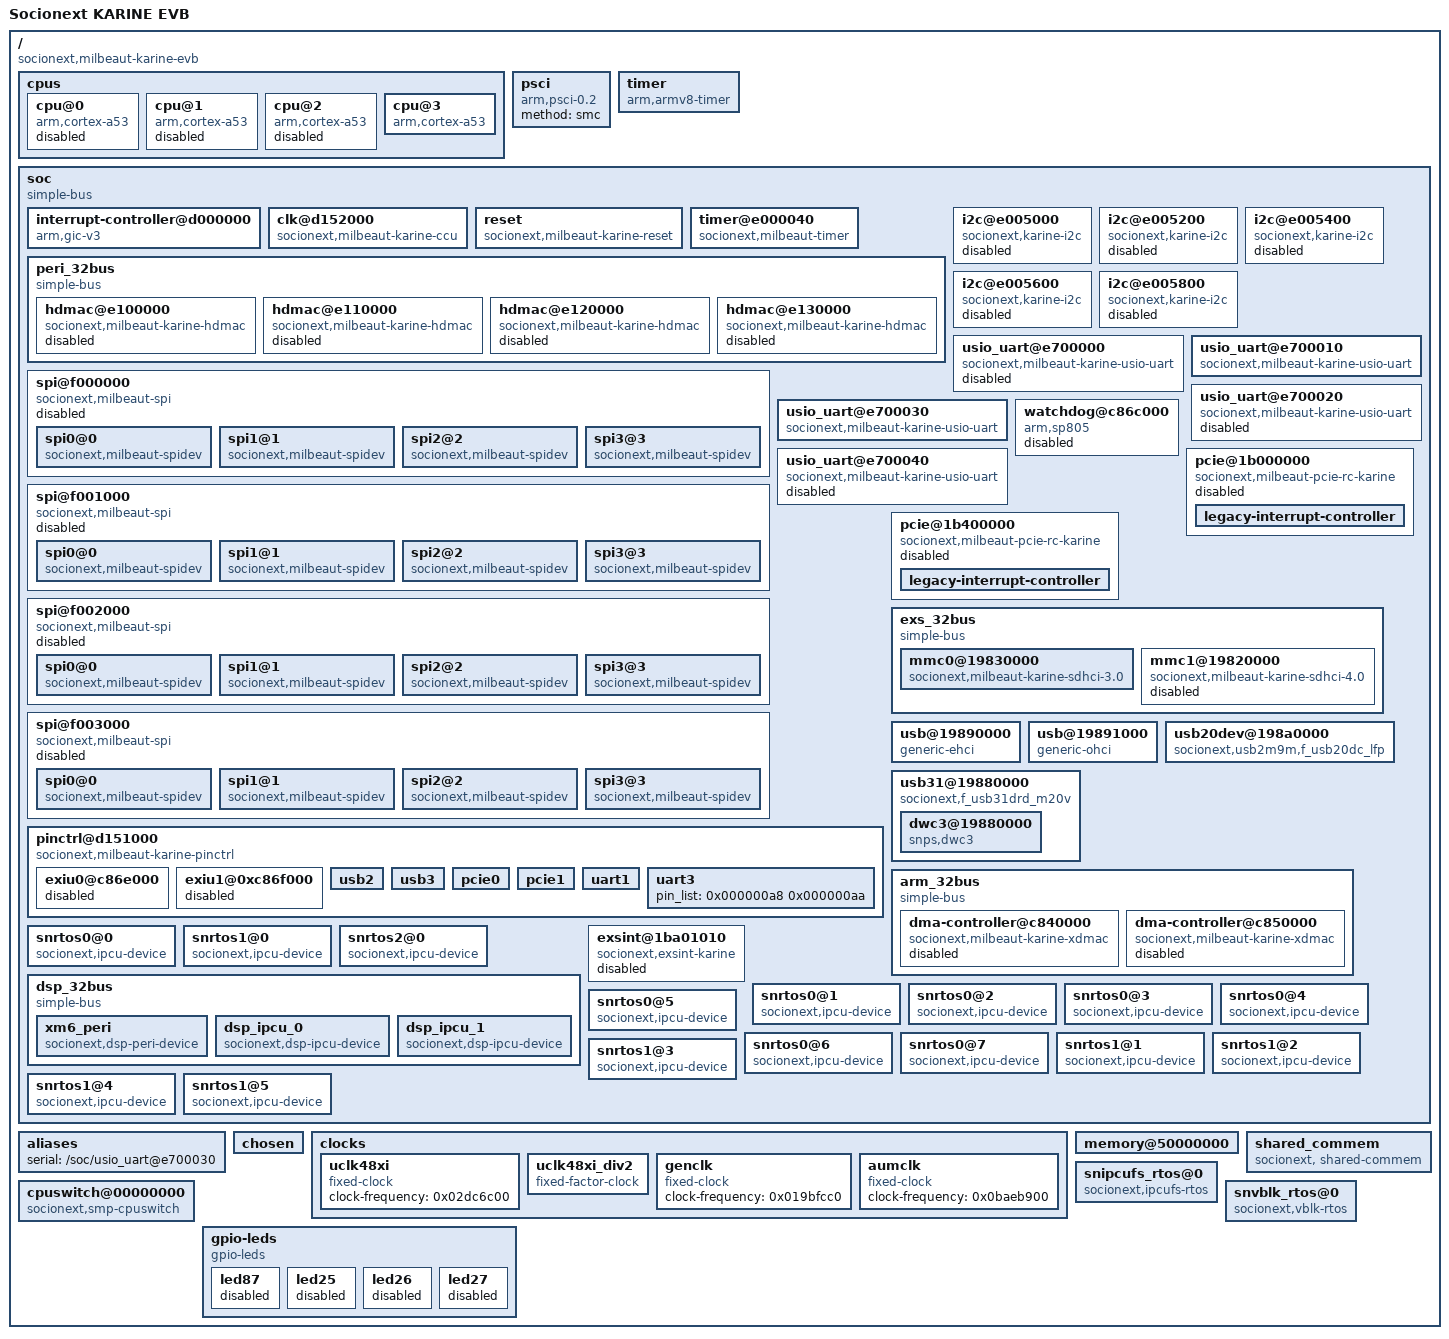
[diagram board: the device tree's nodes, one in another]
/dts-v1/;
// version:		17
// last_comp_version:	16
// boot_cpuid_phys:	0x0

/ {
    compatible = "socionext,milbeaut-karine-evb", "socionext,karine";
    #address-cells = <0x00000002>;
    #size-cells = <0x00000002>;
    interrupt-parent = <0x00000001>;
    model = "Socionext KARINE EVB";
    cpus {
        #address-cells = <0x00000001>;
        #size-cells = <0x00000000>;
        cpu@0 {
            device_type = "cpu";
            compatible = "arm,cortex-a53";
            reg = <0x00000000>;
            enable-method = "psci";
            status = "disabled";
        };
        cpu@1 {
            device_type = "cpu";
            compatible = "arm,cortex-a53";
            reg = <0x00000001>;
            enable-method = "psci";
            status = "disabled";
        };
        cpu@2 {
            device_type = "cpu";
            compatible = "arm,cortex-a53";
            reg = <0x00000002>;
            enable-method = "psci";
            status = "disabled";
        };
        cpu@3 {
            device_type = "cpu";
            compatible = "arm,cortex-a53";
            reg = <0x00000003>;
            enable-method = "psci";
            status = "okay";
        };
    };
    psci {
        compatible = "arm,psci-0.2";
        method = "smc";
    };
    timer {
        compatible = "arm,armv8-timer";
        interrupts = <0x00000001 0x0000000d 0x00000f04 0x00000001 0x0000000e 0x00000f04 0x00000001 0x0000000b 0x00000f04 0x00000001 0x0000000a 0x00000f04>;
    };
    soc {
        compatible = "simple-bus";
        #address-cells = <0x00000002>;
        #size-cells = <0x00000002>;
        ranges = <0x00000000 0x00000000 0x00000000 0x00000000 0x00000000 0xffffffff>;
        dma-ranges = <0x00000000 0x00000000 0x00000000 0x00000000 0x00000000 0xfffffffe>;
        interrupt-controller@d000000 {
            compatible = "arm,gic-v3";
            #interrupt-cells = <0x00000003>;
            interrupt-controller;
            #redistributor-regions = <0x00000001>;
            reg = <0x00000000 0x0d000000 0x00000000 0x00010000 0x00000000 0x0d080000 0x00000000 0x00080000>;
            black-list = <0x00000000 0x00000001 0x00000002 0x00000003 0x00000004 0x00000005 0x00000006 0x0000000a 0x0000000c 0x0000000d 0x00000010 0x00000012 0x00000013 0x00000016 0x00000017 0x00000019 0x0000001c 0x0000001e 0x00000020 0x00000021 0x00000023 0x00000025 0x00000027 0x00000028 0x00000029 0x0000002a 0x0000002c 0x0000002d 0x00000030 0x00000032 0x00000033 0x00000036 0x00000037 0x00000039 0x0000003c 0x0000003e 0x00000040 0x00000041 0x00000043 0x00000045 0x00000047 0x00000048 0x00000049 0x0000004a 0x0000004b 0x0000004c 0x0000004d 0x0000004e 0x0000004f 0x00000050 0x00000051 0x00000052 0x00000053 0x00000054 0x00000055 0x00000056 0x00000057 0x00000058 0x00000059 0x0000005a 0x0000005b 0x00000060 0x00000061 0x00000062 0x00000063 0x00000064 0x00000065 0x00000066 0x00000067 0x00000068 0x00000069 0x0000006a 0x0000006b 0x0000006c 0x0000006d 0x0000006e 0x0000006f 0x00000070 0x00000071 0x00000072 0x00000073 0x00000074 0x00000075 0x00000076 0x00000077 0x00000078 0x00000079 0x0000007a 0x0000007b 0x0000007c 0x0000007d 0x0000007e 0x0000007f 0x00000080 0x00000081 0x00000082 0x00000083 0x00000084 0x00000085 0x00000086 0x00000087 0x00000088 0x00000089 0x0000008a 0x0000008b 0x0000008c 0x0000008d 0x0000008e 0x0000008f 0x00000090 0x00000091 0x00000092 0x00000093 0x00000094 0x00000095 0x00000096 0x00000097 0x00000098 0x00000099 0x0000009a 0x0000009b 0x0000009c 0x0000009d 0x0000009e 0x0000009f 0x000000a0 0x000000a1 0x000000a2 0x000000a3 0x000000a4 0x000000a5 0x000000a6 0x000000a7 0x000000a8 0x000000a9 0x000000aa 0x000000ab 0x000000ac 0x000000ad 0x000000ae 0x000000af 0x000000b0 0x000000b1 0x000000b2 0x000000b3 0x000000b4 0x000000b5 0x000000b6 0x000000b7 0x000000b8 0x000000b9 0x000000ba 0x000000bb 0x000000bc 0x000000bd 0x000000be 0x000000bf 0x000000c0 0x000000c1 0x000000c2 0x000000c3 0x000000c4 0x000000c5 0x000000c6 0x000000c7 0x000000c8 0x000000c9 0x000000ca 0x000000cb 0x000000cc 0x000000cd 0x000000ce 0x000000cf 0x000000d0 0x000000d1 0x000000d2 0x000000d3 0x000000d4 0x000000d5 0x000000d6 0x000000d7 0x000000d8 0x000000d9 0x000000da 0x000000db 0x000000dc 0x000000dd 0x000000de 0x000000df 0x000000e0 0x000000e1 0x000000e2 0x000000e3 0x000000e4 0x000000e5 0x000000e6 0x000000e7 0x000000e8 0x000000e9 0x000000ea 0x000000eb 0x000000ec 0x000000ed 0x000000f2 0x000000f3 0x000000f4 0x000000f5 0x000000f6 0x000000f8 0x000000f9 0x00000102 0x00000103 0x00000108 0x00000109 0x0000010a 0x0000010b 0x0000010c 0x0000010f 0x00000110 0x00000111 0x00000112 0x00000113 0x00000114 0x00000115 0x00000116 0x00000117 0x00000118 0x00000119 0x0000011a 0x0000011b 0x0000011c 0x0000011d 0x0000011e 0x0000011f 0x00000120 0x00000121 0x00000122 0x00000123 0x00000124 0x00000125 0x00000126 0x00000127 0x00000128 0x00000129 0x0000012a 0x0000012b 0x0000012c 0x0000012d 0x0000012e 0x0000012f 0x00000130 0x00000131 0x00000132 0x00000133 0x00000134 0x00000135 0x00000136 0x00000137 0x00000138 0x00000139 0x0000013a 0x0000013b 0x0000013c 0x0000013d 0x0000013e 0x0000013f 0x00000140 0x00000141 0x00000142 0x00000143 0x00000144 0x00000145 0x00000146 0x00000147 0x00000148 0x00000149 0x0000014a 0x0000014b 0x0000014c 0x0000014e 0x00000150 0x00000151 0x00000152 0x00000153 0x00000155 0x00000157 0x00000158 0x00000159 0x0000015a 0x0000015b 0x0000015c 0x0000015d 0x0000015e 0x0000015f 0x00000160 0x00000161 0x00000162 0x00000163 0x00000164 0x00000165 0x00000166 0x00000167 0x00000168 0x00000169 0x0000016a 0x0000016b 0x0000016c 0x0000016d 0x0000016e 0x0000016f 0x00000170 0x00000171 0x00000172 0x00000173 0x00000174 0x00000175 0x00000176 0x00000177 0x00000178 0x00000179 0x0000017a 0x0000017b 0x0000017c 0x0000017d 0x0000017e 0x0000017f 0x00000180 0x00000181 0x00000182 0x00000183 0x00000184 0x00000185 0x00000186 0x00000187 0x00000188 0x00000189 0x0000018a 0x0000018b 0x0000018c 0x0000018d 0x0000018e 0x0000018f 0x00000190 0x00000191 0x00000192 0x00000193 0x00000194 0x00000195 0x00000196 0x00000197 0x00000198 0x00000199 0x0000019a 0x0000019b 0x0000019c 0x0000019d 0x0000019e 0x0000019f>;
            interrupts = <0x00000001 0x00000009 0x00000004>;
            phandle = <0x00000001>;
        };
        clk@d152000 {
            compatible = "socionext,milbeaut-karine-ccu";
            reg = <0x00000000 0x0d152000 0x00000000 0x00003000>;
            #clock-cells = <0x00000001>;
            clocks = <0x00000002 0x00000003 0x00000004>;
            clock-names = "UCLKXI", "AUMCLKI", "GENCLK";
            phandle = <0x00000005>;
        };
        reset {
            compatible = "socionext,milbeaut-karine-reset";
            #reset-cells = <0x00000001>;
            phandle = <0x00000007>;
        };
        timer@e000040 {
            compatible = "socionext,milbeaut-timer";
            reg = <0x00000000 0x0e000040 0x00000000 0x00000020>;
            interrupts = <0x00000000 0x0000010d 0x00000004>;
            clocks = <0x00000005 0x0000000a>;
            rating = <0x0000012c>;
        };
        peri_32bus {
            compatible = "simple-bus";
            #address-cells = <0x00000001>;
            #size-cells = <0x00000001>;
            ranges = <0x00000000 0x00000000 0x00000000 0xffffffff>;
            dma-ranges = <0x00000000 0x00000000 0x00000000 0xfffffffe>;
            hdmac@e100000 {
                compatible = "socionext,milbeaut-karine-hdmac";
                reg = <0x0e100000 0x00010000>;
                interrupts = <0x00000000 0x0000012c 0x00000004 0x00000000 0x0000012d 0x00000004 0x00000000 0x0000012e 0x00000004 0x00000000 0x0000012f 0x00000004 0x00000000 0x00000130 0x00000004 0x00000000 0x00000131 0x00000004 0x00000000 0x00000132 0x00000004 0x00000000 0x00000133 0x00000004>;
                #dma-cells = <0x00000001>;
                priority-rotate;
                clocks = <0x00000005 0x00000010>;
                status = "disabled";
                phandle = <0x00000006>;
            };
            hdmac@e110000 {
                compatible = "socionext,milbeaut-karine-hdmac";
                reg = <0x0e110000 0x00010000>;
                interrupts = <0x00000000 0x00000134 0x00000004 0x00000000 0x00000135 0x00000004 0x00000000 0x00000136 0x00000004 0x00000000 0x00000137 0x00000004 0x00000000 0x00000138 0x00000004 0x00000000 0x00000139 0x00000004 0x00000000 0x0000013a 0x00000004 0x00000000 0x0000013b 0x00000004>;
                #dma-cells = <0x00000001>;
                priority-rotate;
                clocks = <0x00000005 0x00000010>;
                status = "disabled";
            };
            hdmac@e120000 {
                compatible = "socionext,milbeaut-karine-hdmac";
                reg = <0x0e120000 0x00010000>;
                interrupts = <0x00000000 0x0000013c 0x00000004 0x00000000 0x0000013d 0x00000004 0x00000000 0x0000013e 0x00000004 0x00000000 0x0000013f 0x00000004 0x00000000 0x00000140 0x00000004 0x00000000 0x00000141 0x00000004 0x00000000 0x00000142 0x00000004 0x00000000 0x00000143 0x00000004>;
                #dma-cells = <0x00000001>;
                priority-rotate;
                clocks = <0x00000005 0x00000010>;
                status = "disabled";
            };
            hdmac@e130000 {
                compatible = "socionext,milbeaut-karine-hdmac";
                reg = <0x0e130000 0x00010000>;
                interrupts = <0x00000000 0x00000144 0x00000004 0x00000000 0x00000145 0x00000004 0x00000000 0x00000146 0x00000004 0x00000000 0x00000147 0x00000004 0x00000000 0x00000148 0x00000004 0x00000000 0x00000149 0x00000004 0x00000000 0x0000014a 0x00000004 0x00000000 0x0000014b 0x00000004>;
                #dma-cells = <0x00000001>;
                priority-rotate;
                clocks = <0x00000005 0x00000010>;
                status = "disabled";
            };
        };
        spi@f000000 {
            compatible = "socionext,milbeaut-spi";
            clocks = <0x00000005 0x0000001c 0x00000005 0x0000001b>;
            interrupts = <0x00000000 0x0000015a 0x00000004>;
            reg = <0x00000000 0x0f000000 0x00000000 0x00001000>;
            #address-cells = <0x00000001>;
            #size-cells = <0x00000000>;
            dmas = <0x00000006 0x0000001c 0x00000006 0x0000001b>;
            dma-names = "tx", "rx";
            fifo-size = <0x00000080>;
            num-cs = <0x00000004>;
            dma-mode = <0x00000001>;
            status = "disabled";
            spi0@0 {
                compatible = "socionext,milbeaut-spidev";
                reg = <0x00000000>;
                spi-max-frequency = <0x00989680>;
                ssout-cont = <0x00000002>;
            };
            spi1@1 {
                compatible = "socionext,milbeaut-spidev";
                reg = <0x00000001>;
                spi-max-frequency = <0x00989680>;
                ssout-cont = <0x00000002>;
            };
            spi2@2 {
                compatible = "socionext,milbeaut-spidev";
                reg = <0x00000002>;
                spi-max-frequency = <0x00989680>;
                ssout-cont = <0x00000002>;
            };
            spi3@3 {
                compatible = "socionext,milbeaut-spidev";
                reg = <0x00000003>;
                spi-max-frequency = <0x00989680>;
                ssout-cont = <0x00000002>;
            };
        };
        spi@f001000 {
            compatible = "socionext,milbeaut-spi";
            clocks = <0x00000005 0x0000001a 0x00000005 0x00000019>;
            interrupts = <0x00000000 0x0000015b 0x00000004>;
            reg = <0x00000000 0x0f001000 0x00000000 0x00001000>;
            #address-cells = <0x00000001>;
            #size-cells = <0x00000000>;
            dmas = <0x00000006 0x0000001e 0x00000006 0x0000001d>;
            dma-names = "tx", "rx";
            fifo-size = <0x00000040>;
            num-cs = <0x00000004>;
            dma-mode = <0x00000001>;
            status = "disabled";
            spi0@0 {
                compatible = "socionext,milbeaut-spidev";
                reg = <0x00000000>;
                spi-max-frequency = <0x00989680>;
                ssout-cont = <0x00000002>;
            };
            spi1@1 {
                compatible = "socionext,milbeaut-spidev";
                reg = <0x00000001>;
                spi-max-frequency = <0x00989680>;
                ssout-cont = <0x00000002>;
            };
            spi2@2 {
                compatible = "socionext,milbeaut-spidev";
                reg = <0x00000002>;
                spi-max-frequency = <0x00989680>;
                ssout-cont = <0x00000002>;
            };
            spi3@3 {
                compatible = "socionext,milbeaut-spidev";
                reg = <0x00000003>;
                spi-max-frequency = <0x00989680>;
                ssout-cont = <0x00000002>;
            };
        };
        spi@f002000 {
            compatible = "socionext,milbeaut-spi";
            clocks = <0x00000005 0x00000018 0x00000005 0x00000017>;
            interrupts = <0x00000000 0x0000015c 0x00000004>;
            reg = <0x00000000 0x0f002000 0x00000000 0x00001000>;
            #address-cells = <0x00000001>;
            #size-cells = <0x00000000>;
            dmas = <0x00000006 0x00000020 0x00000006 0x0000001f>;
            dma-names = "tx", "rx";
            fifo-size = <0x00000040>;
            num-cs = <0x00000004>;
            dma-mode = <0x00000001>;
            status = "disabled";
            spi0@0 {
                compatible = "socionext,milbeaut-spidev";
                reg = <0x00000000>;
                spi-max-frequency = <0x00989680>;
                ssout-cont = <0x00000002>;
            };
            spi1@1 {
                compatible = "socionext,milbeaut-spidev";
                reg = <0x00000001>;
                spi-max-frequency = <0x00989680>;
                ssout-cont = <0x00000002>;
            };
            spi2@2 {
                compatible = "socionext,milbeaut-spidev";
                reg = <0x00000002>;
                spi-max-frequency = <0x00989680>;
                ssout-cont = <0x00000002>;
            };
            spi3@3 {
                compatible = "socionext,milbeaut-spidev";
                reg = <0x00000003>;
                spi-max-frequency = <0x00989680>;
                ssout-cont = <0x00000002>;
            };
        };
        spi@f003000 {
            compatible = "socionext,milbeaut-spi";
            clocks = <0x00000005 0x00000016 0x00000005 0x00000015>;
            interrupts = <0x00000000 0x0000015d 0x00000004>;
            reg = <0x00000000 0x0f003000 0x00000000 0x00001000>;
            #address-cells = <0x00000001>;
            #size-cells = <0x00000000>;
            dmas = <0x00000006 0x00000022 0x00000006 0x00000021>;
            dma-names = "tx", "rx";
            fifo-size = <0x00000040>;
            num-cs = <0x00000004>;
            dma-mode = <0x00000001>;
            status = "disabled";
            spi0@0 {
                compatible = "socionext,milbeaut-spidev";
                reg = <0x00000000>;
                spi-max-frequency = <0x00989680>;
                ssout-cont = <0x00000002>;
            };
            spi1@1 {
                compatible = "socionext,milbeaut-spidev";
                reg = <0x00000001>;
                spi-max-frequency = <0x00989680>;
                ssout-cont = <0x00000002>;
            };
            spi2@2 {
                compatible = "socionext,milbeaut-spidev";
                reg = <0x00000002>;
                spi-max-frequency = <0x00989680>;
                ssout-cont = <0x00000002>;
            };
            spi3@3 {
                compatible = "socionext,milbeaut-spidev";
                reg = <0x00000003>;
                spi-max-frequency = <0x00989680>;
                ssout-cont = <0x00000002>;
            };
        };
        i2c@e005000 {
            compatible = "socionext,karine-i2c";
            reg = <0x00000000 0x0e005000 0x00000000 0x00000400>;
            interrupts = <0x00000000 0x00000112 0x00000004>;
            clocks = <0x00000005 0x00000012>;
            clock-frequency = <0x000186a0>;
            status = "disabled";
        };
        i2c@e005200 {
            compatible = "socionext,karine-i2c";
            reg = <0x00000000 0x0e005200 0x00000000 0x00000400>;
            interrupts = <0x00000000 0x00000113 0x00000004>;
            clocks = <0x00000005 0x00000012>;
            clock-frequency = <0x000186a0>;
            status = "disabled";
        };
        i2c@e005400 {
            compatible = "socionext,karine-i2c";
            reg = <0x00000000 0x0e005400 0x00000000 0x00000400>;
            interrupts = <0x00000000 0x00000114 0x00000004>;
            clocks = <0x00000005 0x00000012>;
            clock-frequency = <0x000186a0>;
            status = "disabled";
        };
        i2c@e005600 {
            compatible = "socionext,karine-i2c";
            reg = <0x00000000 0x0e005600 0x00000000 0x00000400>;
            interrupts = <0x00000000 0x00000115 0x00000004>;
            clocks = <0x00000005 0x00000012>;
            clock-frequency = <0x000186a0>;
            status = "disabled";
        };
        i2c@e005800 {
            status = "disabled";
            compatible = "socionext,karine-i2c";
            reg = <0x00000000 0x0e005800 0x00000000 0x00000400>;
            interrupts = <0x00000000 0x00000116 0x00000004>;
            clocks = <0x00000005 0x00000012>;
            clock-frequency = <0x000186a0>;
        };
        usio_uart@e700000 {
            compatible = "socionext,milbeaut-karine-usio-uart";
            reg = <0x00000000 0x0e700000 0x00000000 0x00000010>;
            interrupts = <0x00000000 0x0000014c 0x00000004 0x00000000 0x00000153 0x00000004>;
            interrupt-names = "rx", "tx";
            clocks = <0x00000005 0x00000010>;
            status = "disabled";
            index = <0x00000000>;
        };
        usio_uart@e700010 {
            compatible = "socionext,milbeaut-karine-usio-uart";
            reg = <0x00000000 0x0e700010 0x00000000 0x00000010>;
            interrupts = <0x00000000 0x0000014d 0x00000004 0x00000000 0x00000154 0x00000004>;
            interrupt-names = "rx", "tx";
            clocks = <0x00000005 0x00000010>;
            status = "okay";
            index = <0x00000001>;
            uart-flow-enable;
        };
        usio_uart@e700020 {
            compatible = "socionext,milbeaut-karine-usio-uart";
            reg = <0x00000000 0x0e700020 0x00000000 0x00000010>;
            interrupts = <0x00000000 0x0000014e 0x00000004 0x00000000 0x00000155 0x00000004>;
            interrupt-names = "rx", "tx";
            clocks = <0x00000005 0x00000010>;
            status = "disabled";
            index = <0x00000002>;
        };
        usio_uart@e700030 {
            compatible = "socionext,milbeaut-karine-usio-uart";
            reg = <0x00000000 0x0e700030 0x00000000 0x00000010>;
            interrupts = <0x00000000 0x0000014f 0x00000004 0x00000000 0x00000156 0x00000004>;
            interrupt-names = "rx", "tx";
            clocks = <0x00000005 0x00000010>;
            status = "okay";
            index = <0x00000003>;
        };
        usio_uart@e700040 {
            compatible = "socionext,milbeaut-karine-usio-uart";
            reg = <0x00000000 0x0e700040 0x00000000 0x00000010>;
            interrupts = <0x00000000 0x00000150 0x00000004 0x00000000 0x00000157 0x00000004>;
            interrupt-names = "rx", "tx";
            clocks = <0x00000005 0x00000010>;
            status = "disabled";
            index = <0x00000004>;
        };
        watchdog@c86c000 {
            compatible = "arm,sp805", "arm,primecell";
            reg = <0x00000000 0x0c86c000 0x00000000 0x00001000>;
            interrupts = <0x00000000 0x0000000a 0x00000004>;
            clocks = <0x00000005 0x0000000c 0x00000005 0x0000000d>;
            clock-names = "wdog_clk", "apb_pclk";
            status = "disabled";
        };
        pinctrl@d151000 {
            compatible = "socionext,milbeaut-karine-pinctrl";
            reg = <0x00000000 0x0d151000 0x00000000 0x00001000>;
            reg-names = "pinctrl";
            bank-offset = <0x00000000 0x00000020 0x00000060 0x00000080 0x000000a0 0x000000c0 0x000000d0 0x000000e0 0x00000100 0x00000150 0x00000170 0x00000200>;
            gpio-controller;
            #gpio-cells = <0x00000002>;
            interrupt-controller;
            #interrupt-cells = <0x00000002>;
            interrupts = <0x00000000 0x0000003b 0x00000004 0x00000000 0x0000003c 0x00000004 0x00000000 0x0000003d 0x00000004 0x00000000 0x0000003e 0x00000004 0x00000000 0x0000003f 0x00000004 0x00000000 0x00000040 0x00000004 0x00000000 0x00000041 0x00000004 0x00000000 0x00000042 0x00000004 0x00000000 0x00000043 0x00000004 0x00000000 0x00000044 0x00000004 0x00000000 0x00000045 0x00000004 0x00000000 0x00000046 0x00000004 0x00000000 0x00000047 0x00000004 0x00000000 0x00000048 0x00000004 0x00000000 0x00000049 0x00000004 0x00000000 0x0000004a 0x00000004 0x00000000 0x0000004b 0x00000004 0x00000000 0x0000004c 0x00000004 0x00000000 0x0000004d 0x00000004 0x00000000 0x0000004e 0x00000004 0x00000000 0x0000004f 0x00000004 0x00000000 0x00000050 0x00000004 0x00000000 0x00000051 0x00000004 0x00000000 0x00000052 0x00000004 0x00000000 0x00000053 0x00000004 0x00000000 0x00000054 0x00000004 0x00000000 0x00000055 0x00000004 0x00000000 0x00000056 0x00000004 0x00000000 0x00000057 0x00000004 0x00000000 0x00000058 0x00000004 0x00000000 0x00000059 0x00000004 0x00000000 0x0000005a 0x00000004>;
            interrupt-names = "pin-0", "pin-1", "pin-2", "pin-3", "pin-4", "pin-5", "pin-6", "pin-7", "pin-8", "pin-9", "pin-10", "pin-11", "pin-12", "pin-13", "pin-14", "pin-15", "pin-32", "pin-33", "pin-34", "pin-35", "pin-36", "pin-37", "pin-38", "pin-39", "pin-40", "pin-41", "pin-42", "pin-43", "pin-44", "pin-45", "pin-46", "pin-47";
            blacklist = <0x000007ed 0x0000101f 0x0000ffbe 0x0000ff5f 0x0000ffff 0x0000ffff 0x0000ffff 0x0000fdcf 0x0000ffff 0x0000e0ff 0x0000fae0 0x000000ff>;
            io_pin_list = <0x00000000 0x00000001 0x00000002 0x00000003 0x00000004 0x00000005 0x00000006 0x00000007 0x00000008 0x00000009 0x0000000a 0x0000000b 0x0000000c 0x0000000d 0x0000000e 0x0000000f 0x00000010 0x00000011 0x00000012 0x00000013 0x00000014 0x00000015 0x00000016 0x00000017 0x00000018 0x00000019 0x0000001a 0x0000001b 0x0000001c 0x0000001d 0x0000001e 0x0000001f 0x00000030 0x00000031 0x00000032 0x00000033 0x00000036 0x00000037 0x00000038 0x00000039 0x0000003a 0x0000003b 0x00000040 0x00000041 0x00000042 0x00000043 0x00000044 0x00000045 0x00000046 0x00000047 0x00000048 0x00000049 0x0000004a 0x0000004b 0x0000004c 0x00000060 0x00000061 0x00000062 0x00000063 0x00000064 0x00000065 0x00000066 0x00000070 0x00000071 0x0000007a 0x0000007b 0x0000007c 0x00000080 0x00000081 0x00000082 0x00000083 0x00000084 0x00000085 0x00000086 0x00000087 0x00000088 0x00000089 0x0000008a 0x0000008b 0x00000098 0x00000099 0x0000009b 0x0000009c 0x0000009d 0x0000009e 0x0000009f 0x000000a0 0x000000a1 0x000000a3 0x000000a4 0x000000a8 0x000000a9 0x000000aa 0x000000ab 0x000000b8 0x000000b9 0x000000ba 0x000000bb 0x000000bc 0x000000bd 0x000000be 0x000000bf>;
            io_pin_offset = <0x000008b8 0x000008bc 0x000008c0 0x000008c4 0x000008c8 0x000008cc 0x000008d0 0x000008d4 0x000008d8 0x000008dc 0x000008e0 0x000008e4 0x000008e8 0x000008ec 0x000008f0 0x000008f4 0x000008f8 0x000008fc 0x00000900 0x00000904 0x00000908 0x0000090c 0x00000910 0x00000914 0x00000918 0x0000091c 0x00000920 0x00000924 0x00000928 0x0000092c 0x00000930 0x00000934 0x000008a0 0x000008a4 0x000008a8 0x000008ac 0x000008b0 0x000008b4 0x0000087c 0x00000880 0x00000884 0x00000888 0x00000800 0x00000804 0x00000808 0x0000080c 0x00000810 0x00000814 0x00000818 0x0000081c 0x00000858 0x0000085c 0x00000860 0x00000864 0x00000868 0x00000820 0x00000824 0x00000828 0x0000082c 0x00000830 0x00000834 0x00000838 0x0000088c 0x00000890 0x00000894 0x00000898 0x0000089c 0x00000984 0x00000988 0x0000098c 0x00000990 0x00000994 0x00000998 0x0000099c 0x000009a0 0x000009a4 0x000009a8 0x000009ac 0x000009b0 0x00000a24 0x00000a28 0x00000a2c 0x00000a30 0x00000948 0x0000094c 0x00000950 0x00000a34 0x00000a38 0x00000a3c 0x00000a40 0x00000938 0x0000093c 0x00000940 0x00000944 0x00000a44 0x00000a48 0x00000a4c 0x00000a50 0x00000a54 0x00000a58 0x00000a5c 0x00000a60>;
            ranges;
            #address-cells = <0x00000002>;
            #size-cells = <0x00000002>;
            status = "okay";
            phandle = <0x0000000c>;
            exiu0@c86e000 {
                reg = <0x00000000 0x0c86e000 0x00000000 0x00000100>;
                pin_list = <0x00000000 0x00000001 0x00000002 0x00000003 0x00000004 0x00000005 0x00000006 0x00000007 0x00000008 0x00000009 0x0000000a 0x0000000b 0x0000000c 0x0000000d 0x0000000e 0x0000000f>;
                status = "disabled";
            };
            exiu1@0xc86f000 {
                reg = <0x00000000 0x0c86f000 0x00000000 0x00000100>;
                pin_list = <0x00000020 0x00000021 0x00000022 0x00000023 0x00000024 0x00000025 0x00000026 0x00000027 0x00000028 0x00000029 0x0000002a 0x0000002b 0x0000002c 0x0000002d 0x0000002e 0x0000002f>;
                status = "disabled";
            };
            usb2 {
                pin_list = <0x00000098 0x00000099 0x0000009a 0x0000009b 0x0000009c>;
            };
            usb3 {
                pin_list = <0x000000a0 0x000000a1 0x000000a2 0x000000a3 0x000000a4>;
            };
            pcie0 {
                pin_list = <0x000000b8 0x000000ba 0x000000bc 0x000000be>;
            };
            pcie1 {
                pin_list = <0x000000b9 0x000000bb 0x000000bd 0x000000bf>;
            };
            uart1 {
                pin_list = <0x00000035 0x00000074 0x00000075 0x00000079>;
            };
            uart3 {
                pin_list = <0x000000a8 0x000000aa>;
            };
        };
        pcie@1b000000 {
            compatible = "socionext,milbeaut-pcie-rc-karine", "snps,dw-pcie";
            device_type = "pci";
            reg = <0x00000000 0x1b000000 0x00000000 0x00400000 0x00000000 0x1a000000 0x00000000 0x00010000 0x00000000 0x1bb00000 0x00000000 0x00000100>;
            reg-names = "dbi", "config", "ctrl";
            #address-cells = <0x00000003>;
            #size-cells = <0x00000002>;
            clocks = <0x00000005 0x00000001 0x00000005 0x00000000>;
            clock-names = "auxclk", "busclk";
            resets = <0x00000007 0x00000003 0x00000007 0x00000007 0x00000007 0x00000005>;
            reset-names = "pwr", "soft", "dev";
            num-lanes = <0x00000002>;
            num-viewport = <0x00000004>;
            bus-range = <0x00000000 0x000000ff>;
            ranges = <0x81000000 0x00000000 0x00000000 0x00000000 0x1a7f0000 0x00000000 0x00010000 0x82000000 0x00000000 0x1a010000 0x00000000 0x1a010000 0x00000000 0x007e0000>;
            interrupts = <0x00000000 0x000000fb 0x00000004 0x00000000 0x000000fc 0x00000004>;
            interrupt-names = "msi", "dma";
            #interrupt-cells = <0x00000001>;
            interrupt-map-mask = <0x00000000 0x00000000 0x00000000 0x00000007>;
            interrupt-map = <0x00000000 0x00000000 0x00000000 0x00000001 0x00000008 0x00000003 0x00000000 0x00000000 0x00000000 0x00000002 0x00000008 0x00000002 0x00000000 0x00000000 0x00000000 0x00000003 0x00000008 0x00000001 0x00000000 0x00000000 0x00000000 0x00000004 0x00000008 0x00000000>;
            status = "disabled";
            legacy-interrupt-controller {
                interrupt-controller;
                #interrupt-cells = <0x00000001>;
                interrupt-parent = <0x00000001>;
                interrupts = <0x00000000 0x000000fa 0x00000004>;
                phandle = <0x00000008>;
            };
        };
        pcie@1b400000 {
            compatible = "socionext,milbeaut-pcie-rc-karine", "snps,dw-pcie";
            device_type = "pci";
            reg = <0x00000000 0x1b400000 0x00000000 0x00400000 0x00000000 0x1a800000 0x00000000 0x00010000 0x00000000 0x1bb80000 0x00000000 0x00000100>;
            reg-names = "dbi", "config", "ctrl";
            #address-cells = <0x00000003>;
            #size-cells = <0x00000002>;
            clocks = <0x00000005 0x00000001 0x00000005 0x00000000>;
            clock-names = "auxclk", "busclk";
            resets = <0x00000007 0x00000004 0x00000007 0x00000008 0x00000007 0x00000006>;
            reset-names = "pwr", "soft", "dev";
            num-lanes = <0x00000001>;
            num-viewport = <0x00000004>;
            ranges = <0x81000000 0x00000000 0x00000000 0x00000000 0x1aff0000 0x00000000 0x00010000 0x82000000 0x00000000 0x1a810000 0x00000000 0x1a810000 0x00000000 0x007e0000>;
            interrupts = <0x00000000 0x000000fe 0x00000004 0x00000000 0x000000ff 0x00000004>;
            interrupt-names = "msi", "dma";
            #interrupt-cells = <0x00000001>;
            interrupt-map-mask = <0x00000000 0x00000000 0x00000000 0x00000007>;
            interrupt-map = <0x00000000 0x00000000 0x00000000 0x00000001 0x00000009 0x00000003 0x00000000 0x00000000 0x00000000 0x00000002 0x00000009 0x00000002 0x00000000 0x00000000 0x00000000 0x00000003 0x00000009 0x00000001 0x00000000 0x00000000 0x00000000 0x00000004 0x00000009 0x00000000>;
            status = "disabled";
            legacy-interrupt-controller {
                interrupt-controller;
                #interrupt-cells = <0x00000001>;
                interrupt-parent = <0x00000001>;
                interrupts = <0x00000000 0x000000fd 0x00000004>;
                phandle = <0x00000009>;
            };
        };
        exs_32bus {
            compatible = "simple-bus";
            #address-cells = <0x00000001>;
            #size-cells = <0x00000001>;
            ranges = <0x00000000 0x00000000 0x00000000 0xfffffffe>;
            dma-ranges = <0x00000000 0x00000000 0x00000000 0xfffffffe>;
            mmc0@19830000 {
                compatible = "socionext,milbeaut-karine-sdhci-3.0";
                reg = <0x19830000 0x00004000>;
                interrupts = <0x00000000 0x000000ef 0x00000004>;
                bus-width = <0x00000004>;
                clocks = <0x00000005 0x00000003 0x00000005 0x00000002>;
                clock-names = "core", "iface";
                fujitsu,cmd-dat-delay-select;
                status = "okay";
                keep-power-in-suspend;
                non-removable;
                quirk-host-off-card-on;
            };
            mmc1@19820000 {
                status = "disabled";
                compatible = "socionext,milbeaut-karine-sdhci-4.0";
                reg = <0x19820000 0x00004000 0x19828200 0x00000200 0x19828000 0x00000200>;
                reg-names = "uhs1", "uhs2", "uhs2_sn";
                interrupts = <0x00000000 0x000000f2 0x00000004 0x00000000 0x000000f5 0x00000004>;
                interrupt-names = "uhs1", "uhs2";
                voltage-ranges = <0x00000ce4 0x00000ce4>;
                bus-width = <0x00000004>;
                clocks = <0x00000005 0x00000007 0x00000005 0x00000005 0x00000005 0x00000006 0x00000005 0x00000004>;
                clock-names = "core", "iface", "tuning", "aclk";
                cap-sdio-irq;
                sd40_enable;
                uhs2-power-limit = <0x00000004>;
                fujitsu,cmd-dat-delay-select;
                default-uhs1;
            };
        };
        usb@19890000 {
            compatible = "generic-ehci";
            reg = <0x00000000 0x19890000 0x00000000 0x00000100>;
            interrupts = <0x00000000 0x00000105 0x00000004>;
            resets = <0x00000007 0x00000009>;
        };
        usb@19891000 {
            compatible = "generic-ohci";
            reg = <0x00000000 0x19891000 0x00000000 0x00000100>;
            interrupts = <0x00000000 0x00000106 0x00000004>;
        };
        usb20dev@198a0000 {
            compatible = "socionext,usb2m9m,f_usb20dc_lfp";
            reg = <0x00000000 0x198a0000 0x00000000 0x00010000 0x00000000 0x1b800000 0x00000000 0x00001000>;
            reg-names = "udc", "hdmac";
            interrupts = <0x00000000 0x00000104 0x00000004>;
            clocks = <0x00000005 0x00000025>;
            clock-names = "hclk_hdmac";
            resets = <0x00000007 0x00000000>;
        };
        usb31@19880000 {
            compatible = "socionext,f_usb31drd_m20v";
            reg = <0x00000000 0x1ba60000 0x00000000 0x00020000>;
            reg-names = "reg-subsys";
            #address-cells = <0x00000002>;
            #size-cells = <0x00000002>;
            clocks = <0x00000005 0x00000024>;
            clock-names = "apb_bus";
            ranges;
            resets = <0x00000007 0x00000001 0x00000007 0x00000002>;
            reset-names = "reset", "hif";
            dwc3@19880000 {
                compatible = "snps,dwc3";
                reg = <0x00000000 0x19880000 0x00000000 0x00010000>;
                interrupts = <0x00000000 0x000000ee 0x00000004>;
                clocks = <0x00000002 0x00000005 0x00000024 0x0000000a>;
                clock-names = "ref", "bus_early", "suspend";
                snps,has-lpm-erratum = <0x00000001>;
                dr_mode = "peripheral";
                maximum-speed = "super-speed";
            };
        };
        arm_32bus {
            compatible = "simple-bus";
            #address-cells = <0x00000001>;
            #size-cells = <0x00000001>;
            ranges = <0x00000000 0x00000000 0x00000000 0xffffffff>;
            dma-ranges = <0x00000000 0x00000000 0x00000000 0xfffffffe>;
            dma-controller@c840000 {
                compatible = "socionext,milbeaut-karine-xdmac";
                reg = <0x0c840000 0x00001000>;
                interrupts = <0x00000000 0x00000002 0x00000004 0x00000000 0x00000003 0x00000004 0x00000000 0x00000004 0x00000004 0x00000000 0x00000005 0x00000004>;
                #dma-cells = <0x00000001>;
                dma-channels = <0x00000004>;
                status = "disabled";
            };
            dma-controller@c850000 {
                compatible = "socionext,milbeaut-karine-xdmac";
                reg = <0x0c850000 0x00001000>;
                interrupts = <0x00000000 0x00000006 0x00000004 0x00000000 0x00000007 0x00000004 0x00000000 0x00000008 0x00000004 0x00000000 0x00000009 0x00000004>;
                #dma-cells = <0x00000001>;
                dma-channels = <0x00000004>;
                status = "disabled";
                phandle = <0x0000000b>;
            };
        };
        snrtos0@0 {
            compatible = "socionext,ipcu-device";
            reg = <0x00000000 0x0c851000 0x00000000 0x00001000>;
            dst-unit = <0x00000000>;
            dst-mb = <0x00000000>;
            interrupts = <0x00000000 0x0000000b 0x00000004>;
            direction = "recv";
        };
        snrtos1@0 {
            compatible = "socionext,ipcu-device";
            reg = <0x00000000 0x0c852000 0x00000000 0x00001000>;
            dst-unit = <0x00000001>;
            dst-mb = <0x00000000>;
            interrupts = <0x00000000 0x0000001b 0x00000004>;
            direction = "recv";
        };
        snrtos2@0 {
            compatible = "socionext,ipcu-device";
            reg = <0x00000000 0x0c853000 0x00000000 0x00001000>;
        };
        dsp_32bus {
            compatible = "simple-bus";
            #address-cells = <0x00000001>;
            #size-cells = <0x00000001>;
            ranges = <0x00000000 0x00000000 0x00000000 0xfffffffe>;
            dma-ranges = <0x00000000 0x00000000 0x00000000 0xfffffffe>;
            xm6_peri {
                compatible = "socionext,dsp-peri-device";
                reg = <0x1d000000 0x000000cc 0x1c000000 0x00080000 0x1c200000 0x00010000>;
                dmas = <0x0000000b 0x00000000>;
                dma-names = "your_xdmac";
                status = "okay";
            };
            dsp_ipcu_0 {
                compatible = "socionext,dsp-ipcu-device";
                reg = <0x1d002000 0x00000904>;
                interrupts = <0x00000000 0x0000005c 0x00000004>;
                dst-mb = <0x00000000>;
                src-int-ch = <0x00000000>;
                dst-int-ch = <0x00000004>;
                direction = "send";
                status = "okay";
            };
            dsp_ipcu_1 {
                compatible = "socionext,dsp-ipcu-device";
                interrupts = <0x00000000 0x0000005d 0x00000004>;
                dst-mb = <0x00000001>;
                src-int-ch = <0x00000004>;
                dst-int-ch = <0x00000001>;
                direction = "recv";
                status = "okay";
            };
        };
        exsint@1ba01010 {
            status = "disabled";
            compatible = "socionext,exsint-karine";
            #address-cells = <0x00000001>;
            #size-cells = <0x00000001>;
            reg = <0x00000000 0x1ba01010 0x00000000 0x00000004 0x00000000 0x1ba00024 0x00000000 0x00000004>;
            ret-names = "intstat", "intmsk";
            interrupts = <0x00000000 0x000000f7 0x00000004>;
        };
        snrtos0@1 {
            compatible = "socionext,ipcu-device";
            dst-unit = <0x00000000>;
            dst-mb = <0x00000001>;
            interrupts = <0x00000000 0x00000014 0x00000004>;
            direction = "send";
        };
        snrtos0@2 {
            compatible = "socionext,ipcu-device";
            dst-unit = <0x00000000>;
            dst-mb = <0x00000002>;
            interrupts = <0x00000000 0x00000015 0x00000004>;
            direction = "send";
        };
        snrtos0@3 {
            compatible = "socionext,ipcu-device";
            dst-unit = <0x00000000>;
            dst-mb = <0x00000003>;
            interrupts = <0x00000000 0x0000000e 0x00000004>;
            direction = "recv";
        };
        snrtos0@4 {
            compatible = "socionext,ipcu-device";
            dst-unit = <0x00000000>;
            dst-mb = <0x00000004>;
            interrupts = <0x00000000 0x0000000f 0x00000004>;
            direction = "recv";
        };
        snrtos0@5 {
            compatible = "socionext,ipcu-device";
            dst-unit = <0x00000000>;
            dst-mb = <0x00000005>;
            interrupts = <0x00000000 0x00000018 0x00000004>;
            direction = "send";
        };
        snrtos0@6 {
            compatible = "socionext,ipcu-device";
            dst-unit = <0x00000000>;
            dst-mb = <0x00000006>;
            interrupts = <0x00000000 0x00000011 0x00000004>;
            direction = "recv";
        };
        snrtos0@7 {
            compatible = "socionext,ipcu-device";
            dst-unit = <0x00000000>;
            dst-mb = <0x00000007>;
            interrupts = <0x00000000 0x0000001a 0x00000004>;
            direction = "send";
        };
        snrtos1@1 {
            compatible = "socionext,ipcu-device";
            dst-unit = <0x00000001>;
            dst-mb = <0x00000001>;
            interrupts = <0x00000000 0x00000024 0x00000004>;
            direction = "send";
        };
        snrtos1@2 {
            compatible = "socionext,ipcu-device";
            dst-unit = <0x00000001>;
            dst-mb = <0x00000002>;
            interrupts = <0x00000000 0x0000001d 0x00000004>;
            direction = "recv";
        };
        snrtos1@3 {
            compatible = "socionext,ipcu-device";
            dst-unit = <0x00000001>;
            dst-mb = <0x00000003>;
            interrupts = <0x00000000 0x00000026 0x00000004>;
            direction = "send";
        };
        snrtos1@4 {
            compatible = "socionext,ipcu-device";
            dst-unit = <0x00000001>;
            dst-mb = <0x00000004>;
            src-int-ch = <0x0000000a>;
            dst-int-ch = <0x00000004>;
            interrupts = <0x00000000 0x0000001f 0x00000004>;
            direction = "recv";
        };
        snrtos1@5 {
            compatible = "socionext,ipcu-device";
            dst-unit = <0x00000001>;
            dst-mb = <0x00000005>;
            src-int-ch = <0x0000000b>;
            dst-int-ch = <0x00000005>;
            interrupts = <0x00000000 0x00000026 0x00000004>;
            direction = "send";
        };
    };
    aliases {
        serial = "/soc/usio_uart@e700030";
    };
    chosen {
        bootargs = "consoleblank=0 init=/sbin/finit root=/dev/ipcublk rootwait ro console=ttyUSI3,115200n8 nr_cpus=4 maxcpus=1";
        stdout-path = "serial:115200n8";
    };
    clocks {
        uclk48xi {
            compatible = "fixed-clock";
            #clock-cells = <0x00000000>;
            clock-frequency = <0x02dc6c00>;
            phandle = <0x00000002>;
        };
        uclk48xi_div2 {
            compatible = "fixed-factor-clock";
            #clock-cells = <0x00000000>;
            clocks = <0x00000002>;
            clock-div = <0x00000002>;
            clock-mult = <0x00000001>;
            phandle = <0x0000000a>;
        };
        genclk {
            compatible = "fixed-clock";
            #clock-cells = <0x00000000>;
            clock-frequency = <0x019bfcc0>;
            phandle = <0x00000004>;
        };
        aumclk {
            compatible = "fixed-clock";
            #clock-cells = <0x00000000>;
            clock-frequency = <0x0baeb900>;
            phandle = <0x00000003>;
        };
    };
    memory@50000000 {
        device_type = "memory";
        reg = <0x00000000 0x50000000 0x00000000 0x08000000>;
    };
    shared_commem {
        compatible = "socionext, shared-commem";
        address64;
        buf-addr = <0x00000000 0x58000008>;
        buf-size = <0x00000000 0x58000010>;
        sync-addr = <0x00000000 0x58000018>;
        sync-size = <0x00000000 0x58000020>;
        rd-pointer-addr = <0x00000000 0x58000028>;
        rd-pointer-size = <0x00000000 0x58000030>;
        wt-pointer-addr = <0x00000000 0x58000038>;
        wt-pointer-size = <0x00000000 0x58000040>;
        movie-rec-addr = <0x00000000 0x58000048>;
        movie-rec-size = <0x00000000 0x58000050>;
        term-io-addr = <0x00000000 0x58000058>;
        term-io-size = <0x00000000 0x58000060>;
    };
    cpuswitch@00000000 {
        status = "okay";
        compatible = "socionext,smp-cpuswitch";
        #address-cells = <0x00000002>;
        #size-cells = <0x00000002>;
        reg = <0x00000000 0x0d154344 0x00000000 0x00000004>;
        sgi_no = <0x00000008>;
    };
    snipcufs_rtos@0 {
        compatible = "socionext,ipcufs-rtos";
        ipcu_unit = <0x00000000>;
        ipcu_mb = <0x00000002 0x00000003>;
    };
    snvblk_rtos@0 {
        compatible = "socionext,vblk-rtos";
        ipcu_unit = <0x00000001>;
        ipcu_mb = <0x00000001 0x00000000>;
    };
    gpio-leds {
        compatible = "gpio-leds";
        led87 {
            status = "disabled";
            lavel = "lled87";
            gpios = <0x0000000c 0x00000037 0x00000000>;
            linux,default-trigger = "off";
        };
        led25 {
            status = "disabled";
            lavel = "lled25";
            gpios = <0x0000000c 0x00000015 0x00000000>;
            linux,default-trigger = "off";
        };
        led26 {
            status = "disabled";
            lavel = "lled26";
            gpios = <0x0000000c 0x00000016 0x00000000>;
            linux,default-trigger = "off";
        };
        led27 {
            status = "disabled";
            lavel = "lled27";
            gpios = <0x0000000c 0x00000017 0x00000000>;
            linux,default-trigger = "off";
        };
    };
};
